VERSION ""

NS_ :

BS_:

BU_: XXX

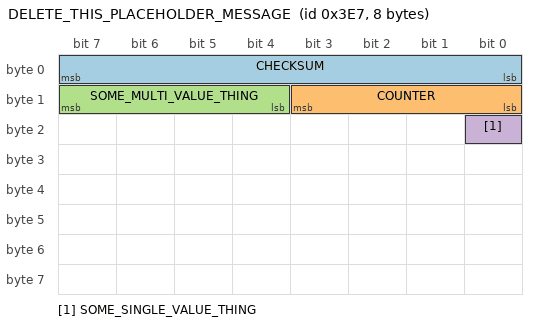
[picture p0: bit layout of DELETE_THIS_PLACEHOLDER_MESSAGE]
BO_ 999 DELETE_THIS_PLACEHOLDER_MESSAGE: 8 XXX
 SG_ CHECKSUM : 0|8@1+ (1,0) [0|255] ""  XXX
 SG_ COUNTER : 8|4@1+ (1,0) [0|15] ""  XXX
 SG_ SOME_MULTI_VALUE_THING : 12|4@1+ (1,0) [0|7] ""  XXX
 SG_ SOME_SINGLE_VALUE_THING : 16|1@1+ (1,0) [0|1] ""  XXX

CM_ SG_ 999 SOMETHING_ELSE "Example of a comment on a specific signal" ;

VAL_ 999 SOME_MULTI_VALUE_THING 0 "init" 1 "foo" 2 "bar" 3 "baz" ;
